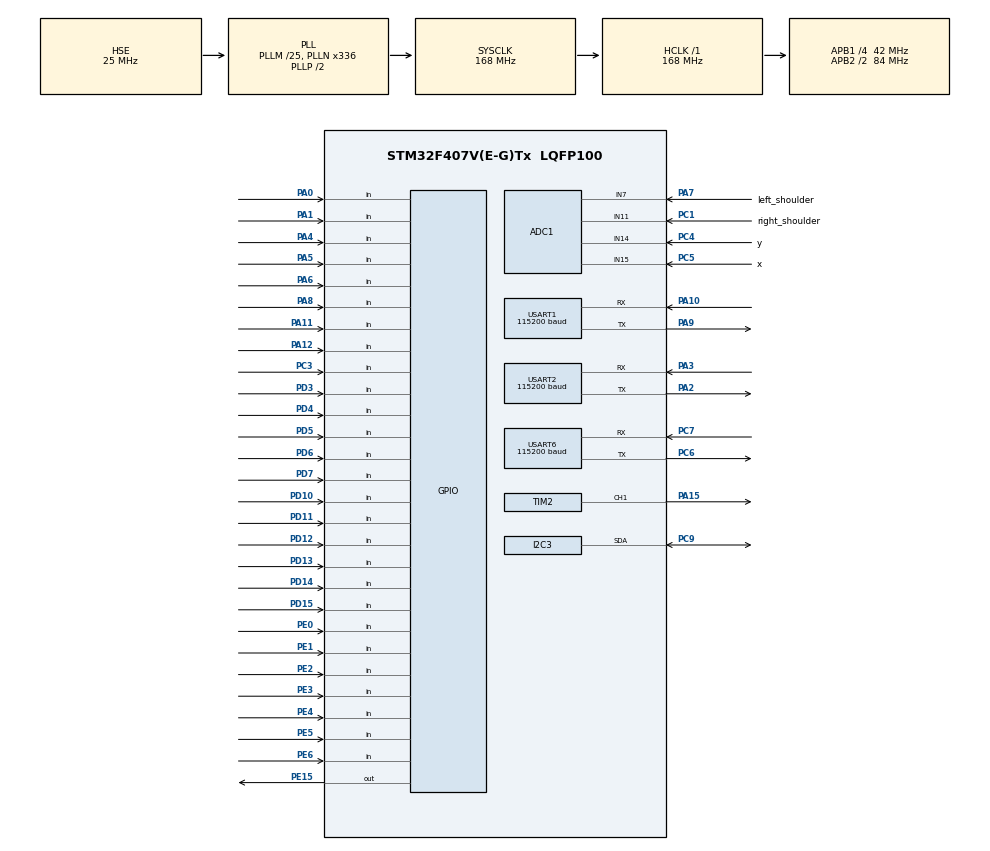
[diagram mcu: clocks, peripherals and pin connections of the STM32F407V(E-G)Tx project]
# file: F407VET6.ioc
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ADC1.Channel-0\#ChannelRegularConversion=ADC_CHANNEL_14
ADC1.Channel-1\#ChannelRegularConversion=ADC_CHANNEL_15
ADC1.Channel-2\#ChannelRegularConversion=ADC_CHANNEL_7
ADC1.Channel-3\#ChannelRegularConversion=ADC_CHANNEL_11
ADC1.NbrOfConversion=4
ADC1.NbrOfConversionFlag=1
ADC1.Rank-0\#ChannelRegularConversion=1
ADC1.Rank-1\#ChannelRegularConversion=2
ADC1.Rank-2\#ChannelRegularConversion=3
ADC1.Rank-3\#ChannelRegularConversion=4
ADC1.SamplingTime-0\#ChannelRegularConversion=ADC_SAMPLETIME_144CYCLES
ADC1.SamplingTime-1\#ChannelRegularConversion=ADC_SAMPLETIME_144CYCLES
ADC1.SamplingTime-2\#ChannelRegularConversion=ADC_SAMPLETIME_144CYCLES
ADC1.SamplingTime-3\#ChannelRegularConversion=ADC_SAMPLETIME_144CYCLES
ADC1.ScanConvMode=ENABLE
ADC1.master=1
Dma.ADC1.0.Direction=DMA_PERIPH_TO_MEMORY
Dma.ADC1.0.FIFOMode=DMA_FIFOMODE_DISABLE
Dma.ADC1.0.Instance=DMA2_Stream0
Dma.ADC1.0.MemDataAlignment=DMA_MDATAALIGN_HALFWORD
Dma.ADC1.0.MemInc=DMA_MINC_ENABLE
Dma.ADC1.0.Mode=DMA_NORMAL
Dma.ADC1.0.PeriphDataAlignment=DMA_PDATAALIGN_HALFWORD
Dma.ADC1.0.PeriphInc=DMA_PINC_DISABLE
Dma.ADC1.0.Priority=DMA_PRIORITY_LOW
Dma.Request0=ADC1
Dma.Request1=USART6_RX
Dma.Request2=USART6_TX
Dma.USART6_RX.1.Direction=DMA_PERIPH_TO_MEMORY
Dma.USART6_RX.1.FIFOMode=DMA_FIFOMODE_DISABLE
Dma.USART6_RX.1.Instance=DMA2_Stream1
Dma.USART6_RX.1.MemDataAlignment=DMA_MDATAALIGN_BYTE
Dma.USART6_RX.1.MemInc=DMA_MINC_ENABLE
Dma.USART6_RX.1.Mode=DMA_NORMAL
Dma.USART6_RX.1.PeriphDataAlignment=DMA_PDATAALIGN_BYTE
Dma.USART6_RX.1.PeriphInc=DMA_PINC_DISABLE
Dma.USART6_RX.1.Priority=DMA_PRIORITY_LOW
Dma.USART6_TX.2.Direction=DMA_MEMORY_TO_PERIPH
Dma.USART6_TX.2.FIFOMode=DMA_FIFOMODE_DISABLE
Dma.USART6_TX.2.Instance=DMA2_Stream6
Dma.USART6_TX.2.MemDataAlignment=DMA_MDATAALIGN_BYTE
Dma.USART6_TX.2.MemInc=DMA_MINC_ENABLE
Dma.USART6_TX.2.Mode=DMA_NORMAL
Dma.USART6_TX.2.PeriphDataAlignment=DMA_PDATAALIGN_BYTE
Dma.USART6_TX.2.PeriphInc=DMA_PINC_DISABLE
Dma.USART6_TX.2.Priority=DMA_PRIORITY_LOW
FREERTOS.BinarySemaphores01=myWIFIsuc,Dynamic,NULL,Depleted;myPacksuc,Dynamic,NULL,Depleted
FREERTOS.Queues01=ScanToTrans,1,remote_data,0,Dynamic,NULL,NULL
FREERTOS.Tasks01=myScanTask,24,256,ScanTask,As weak,NULL,Dynamic,NULL,NULL;myTransmitTask,24,256,TransmitTask,As weak,NULL,Dynamic,NULL,NULL;myWifiTask,24,256,WifiTask,As weak,NULL,Dynamic,NULL,NULL
Mcu.Family=STM32F4
Mcu.Name=STM32F407V(E-G)Tx
Mcu.Package=LQFP100
NVIC.ADC_IRQn=true\:5\:0\:false\:false\:true\:true\:true\:true\:true
NVIC.DMA2_Stream0_IRQn=true\:5\:0\:false\:false\:true\:true\:false\:true\:true
NVIC.DMA2_Stream1_IRQn=true\:5\:0\:false\:false\:true\:true\:false\:true\:true
NVIC.DMA2_Stream6_IRQn=true\:5\:0\:false\:false\:true\:true\:false\:true\:true
NVIC.PriorityGroup=NVIC_PRIORITYGROUP_4
NVIC.TIM1_UP_TIM10_IRQn=true\:15\:0\:false\:false\:true\:false\:false\:true\:true
NVIC.TimeBase=TIM1_UP_TIM10_IRQn
NVIC.TimeBaseIP=TIM1
PA0-WKUP.GPIO_PuPd=GPIO_PULLUP
PA0-WKUP.Signal=GPIO_Input
PA1.GPIO_PuPd=GPIO_PULLUP
PA1.Signal=GPIO_Input
PA10.Mode=Asynchronous
PA10.Signal=USART1_RX
PA11.GPIO_PuPd=GPIO_PULLUP
PA11.Signal=GPIO_Input
PA12.GPIO_PuPd=GPIO_PULLUP
PA12.Signal=GPIO_Input
PA13.Mode=Serial_Wire
PA13.Signal=SYS_JTMS-SWDIO
PA14.Mode=Serial_Wire
PA14.Signal=SYS_JTCK-SWCLK
PA15.GPIO_Speed=GPIO_SPEED_FREQ_LOW
PA15.Signal=S_TIM2_CH1_ETR
PA2.Mode=Asynchronous
PA2.Signal=USART2_TX
PA3.Mode=Asynchronous
PA3.Signal=USART2_RX
PA4.GPIO_PuPd=GPIO_PULLUP
PA4.Signal=GPIO_Input
PA5.GPIO_PuPd=GPIO_PULLUP
PA5.Signal=GPIO_Input
PA6.GPIO_PuPd=GPIO_PULLUP
PA6.Signal=GPIO_Input
PA7.GPIO_Label=left_shoulder
PA7.Signal=ADCx_IN7
PA8.GPIO_PuPd=GPIO_PULLUP
PA8.Signal=GPIO_Input
PA9.Mode=Asynchronous
PA9.Signal=USART1_TX
PC1.GPIO_Label=right_shoulder
PC1.Signal=ADCx_IN11
PC3.GPIO_PuPd=GPIO_PULLUP
PC3.Signal=GPIO_Input
PC4.GPIO_Label=y
PC4.Signal=ADCx_IN14
PC5.GPIO_Label=x
PC5.Signal=ADCx_IN15
PC6.Mode=Asynchronous
PC6.Signal=USART6_TX
PC7.Mode=Asynchronous
PC7.Signal=USART6_RX
PC9.Mode=I2C
PC9.Signal=I2C3_SDA
PD10.GPIO_PuPd=GPIO_PULLUP
PD10.Signal=GPIO_Input
PD11.GPIO_PuPd=GPIO_PULLUP
PD11.Signal=GPIO_Input
PD12.GPIO_PuPd=GPIO_PULLUP
PD12.Signal=GPIO_Input
PD13.GPIO_PuPd=GPIO_PULLUP
PD13.Signal=GPIO_Input
PD14.GPIO_PuPd=GPIO_PULLUP
PD14.Signal=GPIO_Input
PD15.GPIO_PuPd=GPIO_PULLUP
PD15.Signal=GPIO_Input
PD3.GPIO_PuPd=GPIO_PULLUP
PD3.Signal=GPIO_Input
PD4.GPIO_PuPd=GPIO_PULLUP
PD4.Signal=GPIO_Input
PD5.GPIO_PuPd=GPIO_PULLUP
PD5.Signal=GPIO_Input
PD6.GPIO_PuPd=GPIO_PULLUP
PD6.Signal=GPIO_Input
PD7.GPIO_PuPd=GPIO_PULLUP
PD7.Signal=GPIO_Input
PE0.GPIO_PuPd=GPIO_PULLUP
PE0.Signal=GPIO_Input
PE1.GPIO_PuPd=GPIO_PULLUP
PE1.Signal=GPIO_Input
PE15.GPIO_PuPd=GPIO_PULLDOWN
PE15.GPIO_Speed=GPIO_SPEED_FREQ_HIGH
PE15.Signal=GPIO_Output
PE2.GPIO_PuPd=GPIO_PULLUP
PE2.Signal=GPIO_Input
PE3.GPIO_PuPd=GPIO_PULLUP
PE3.Signal=GPIO_Input
PE4.GPIO_PuPd=GPIO_PULLUP
PE4.Signal=GPIO_Input
PE5.GPIO_PuPd=GPIO_PULLUP
PE5.Signal=GPIO_Input
PE6.GPIO_PuPd=GPIO_PULLUP
PE6.Signal=GPIO_Input
PH0-OSC_IN.Mode=HSE-External-Oscillator
PH0-OSC_IN.Signal=RCC_OSC_IN
PH1-OSC_OUT.Mode=HSE-External-Oscillator
PH1-OSC_OUT.Signal=RCC_OSC_OUT
ProjectManager.HeapSize=0x200
ProjectManager.StackSize=0x400
ProjectManager.TargetToolchain=MDK-ARM V5.32
RCC.48MHZClocksFreq_Value=84000000
RCC.AHBFreq_Value=168000000
RCC.APB1CLKDivider=RCC_HCLK_DIV4
RCC.APB1Freq_Value=42000000
RCC.APB1TimFreq_Value=84000000
RCC.APB2CLKDivider=RCC_HCLK_DIV2
RCC.APB2Freq_Value=84000000
RCC.APB2TimFreq_Value=168000000
RCC.CortexFreq_Value=168000000
RCC.HCLKFreq_Value=168000000
RCC.HSE_VALUE=25000000
RCC.HSI_VALUE=16000000
RCC.LSE_VALUE=32768
RCC.PLLM=25
RCC.PLLN=336
RCC.PLLSourceVirtual=RCC_PLLSOURCE_HSE
RCC.SYSCLKFreq_VALUE=168000000
RCC.SYSCLKSource=RCC_SYSCLKSOURCE_PLLCLK
RCC.VCOOutputFreq_Value=336000000
SH.ADCx_IN11.0=ADC1_IN11,IN11
SH.ADCx_IN14.0=ADC1_IN14,IN14
SH.ADCx_IN15.0=ADC1_IN15,IN15
SH.ADCx_IN7.0=ADC1_IN7,IN7
SH.S_TIM2_CH1_ETR.0=TIM2_CH1,PWM Generation1 CH1
TIM2.AutoReloadPreload=TIM_AUTORELOAD_PRELOAD_DISABLE
TIM2.Channel-PWM\ Generation1\ CH1=TIM_CHANNEL_1
TIM2.OC1Preload_PWM=DISABLE
TIM2.Period=28965
TIM2.Prescaler=0
TIM2.Pulse-PWM\ Generation1\ CH1=14482
USART1.BaudRate=115200
USART1.VirtualMode=VM_ASYNC
USART2.BaudRate=115200
USART2.VirtualMode=VM_ASYNC
USART6.BaudRate=115200
USART6.VirtualMode=VM_ASYNC
VP_FREERTOS_VS_CMSIS_V2.Mode=CMSIS_V2
VP_SYS_VS_tim1.Mode=TIM1
VP_TIM2_VS_ClockSourceINT.Mode=Internal
board=custom

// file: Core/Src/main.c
/* USER CODE BEGIN Header */
/**
  ******************************************************************************
  * @file           : main.c
  * @brief          : Main program body
  ******************************************************************************
  * @attention
  *
  * Copyright (c) 2026 STMicroelectronics.
  * All rights reserved.
  *
  * This software is licensed under terms that can be found in the LICENSE file
  * in the root directory of this software component.
  * If no LICENSE file comes with this software, it is provided AS-IS.
  *
  ******************************************************************************
  */
/* USER CODE END Header */
#include "main.h"
#include "cmsis_os.h"
#include "adc.h"
#include "dma.h"
#include "tim.h"
#include "usart.h"
#include "gpio.h"

/* USER CODE BEGIN Includes */
#include "mymain.h"
/* USER CODE END Includes */

/* USER CODE BEGIN PV */
/* USER CODE BEGIN PV */

/* USER CODE END PV */

void SystemClock_Config(void);
void MX_FREERTOS_Init(void);

int main(void)
{

  /* MCU Configuration--------------------------------------------------------*/

  /* Reset of all peripherals, Initializes the Flash interface and the Systick. */
  HAL_Init();

  /* Configure the system clock */
  SystemClock_Config();

  /* Initialize all configured peripherals */
  MX_GPIO_Init();
  MX_DMA_Init();
  MX_USART1_UART_Init();
  MX_USART2_UART_Init();
  MX_USART6_UART_Init();
  MX_ADC1_Init();
  MX_TIM2_Init();

  /* Init scheduler */
  osKernelInitialize();  /* Call init function for freertos objects (in cmsis_os2.c) */
  MX_FREERTOS_Init();

  /* Start scheduler */
  osKernelStart();

  /* We should never get here as control is now taken by the scheduler */

  /* Infinite loop */
  while (1)
  {

  }
}

void SystemClock_Config(void)
{
  RCC_OscInitTypeDef RCC_OscInitStruct = {0};
  RCC_ClkInitTypeDef RCC_ClkInitStruct = {0};

  /** Configure the main internal regulator output voltage
  */
  __HAL_RCC_PWR_CLK_ENABLE();
  __HAL_PWR_VOLTAGESCALING_CONFIG(PWR_REGULATOR_VOLTAGE_SCALE1);

  /** Initializes the RCC Oscillators according to the specified parameters
  * in the RCC_OscInitTypeDef structure.
  */
  RCC_OscInitStruct.OscillatorType = RCC_OSCILLATORTYPE_HSE;
  RCC_OscInitStruct.HSEState = RCC_HSE_ON;
  RCC_OscInitStruct.PLL.PLLState = RCC_PLL_ON;
  RCC_OscInitStruct.PLL.PLLSource = RCC_PLLSOURCE_HSE;
  RCC_OscInitStruct.PLL.PLLM = 25;
  RCC_OscInitStruct.PLL.PLLN = 336;
  RCC_OscInitStruct.PLL.PLLP = RCC_PLLP_DIV2;
  RCC_OscInitStruct.PLL.PLLQ = 4;
  if (HAL_RCC_OscConfig(&RCC_OscInitStruct) != HAL_OK)
  {
    Error_Handler();
  }

  /** Initializes the CPU, AHB and APB buses clocks
  */
  RCC_ClkInitStruct.ClockType = RCC_CLOCKTYPE_HCLK|RCC_CLOCKTYPE_SYSCLK
                              |RCC_CLOCKTYPE_PCLK1|RCC_CLOCKTYPE_PCLK2;
  RCC_ClkInitStruct.SYSCLKSource = RCC_SYSCLKSOURCE_PLLCLK;
  RCC_ClkInitStruct.AHBCLKDivider = RCC_SYSCLK_DIV1;
  RCC_ClkInitStruct.APB1CLKDivider = RCC_HCLK_DIV4;
  RCC_ClkInitStruct.APB2CLKDivider = RCC_HCLK_DIV2;

  if (HAL_RCC_ClockConfig(&RCC_ClkInitStruct, FLASH_LATENCY_5) != HAL_OK)
  {
    Error_Handler();
  }
}

void HAL_TIM_PeriodElapsedCallback(TIM_HandleTypeDef *htim)
{
  if (htim->Instance == TIM1)
  {
    HAL_IncTick();
  }
}

void Error_Handler(void)
{
  __disable_irq();
  while (1)
  {
  }
}

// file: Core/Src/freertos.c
/* USER CODE BEGIN Header */
/**
  ******************************************************************************
  * File Name          : freertos.c
  * Description        : Code for freertos applications
  ******************************************************************************
  * @attention
  *
  * Copyright (c) 2026 STMicroelectronics.
  * All rights reserved.
  *
  * This software is licensed under terms that can be found in the LICENSE file
  * in the root directory of this software component.
  * If no LICENSE file comes with this software, it is provided AS-IS.
  *
  ******************************************************************************
  */
/* USER CODE END Header */

#include "FreeRTOS.h"
#include "task.h"
#include "main.h"
#include "cmsis_os.h"

/* USER CODE BEGIN Includes */
#include "mymain.h"

/* USER CODE END Includes */

/* Definitions for myScanTask */
osThreadId_t myScanTaskHandle;
const osThreadAttr_t myScanTask_attributes = {
  .name = "myScanTask",
  .stack_size = 256 * 4,
  .priority = (osPriority_t) osPriorityNormal,
};
/* Definitions for myTransmitTask */
osThreadId_t myTransmitTaskHandle;
const osThreadAttr_t myTransmitTask_attributes = {
  .name = "myTransmitTask",
  .stack_size = 256 * 4,
  .priority = (osPriority_t) osPriorityNormal,
};
/* Definitions for myWifiTask */
osThreadId_t myWifiTaskHandle;
const osThreadAttr_t myWifiTask_attributes = {
  .name = "myWifiTask",
  .stack_size = 256 * 4,
  .priority = (osPriority_t) osPriorityNormal,
};
/* Definitions for ScanToTrans */
osMessageQueueId_t ScanToTransHandle;
const osMessageQueueAttr_t ScanToTrans_attributes = {
  .name = "ScanToTrans"
};
/* Definitions for myWIFIsuc */
osSemaphoreId_t myWIFIsucHandle;
const osSemaphoreAttr_t myWIFIsuc_attributes = {
  .name = "myWIFIsuc"
};
/* Definitions for myPacksuc */
osSemaphoreId_t myPacksucHandle;
const osSemaphoreAttr_t myPacksuc_attributes = {
  .name = "myPacksuc"
};

void ScanTask(void *argument);
void TransmitTask(void *argument);
void WifiTask(void *argument);

void MX_FREERTOS_Init(void); /* (MISRA C 2004 rule 8.1) */

void MX_FREERTOS_Init(void) {

  /* Create the semaphores(s) */
  /* creation of myWIFIsuc */
  myWIFIsucHandle = osSemaphoreNew(1, 0, &myWIFIsuc_attributes);

  /* creation of myPacksuc */
  myPacksucHandle = osSemaphoreNew(1, 0, &myPacksuc_attributes);

  /* Create the queue(s) */
  /* creation of ScanToTrans */
  ScanToTransHandle = osMessageQueueNew (1, sizeof(remote_data), &ScanToTrans_attributes);

  /* Create the thread(s) */
  /* creation of myScanTask */
  myScanTaskHandle = osThreadNew(ScanTask, NULL, &myScanTask_attributes);

  /* creation of myTransmitTask */
  myTransmitTaskHandle = osThreadNew(TransmitTask, NULL, &myTransmitTask_attributes);

  /* creation of myWifiTask */
  myWifiTaskHandle = osThreadNew(WifiTask, NULL, &myWifiTask_attributes);

}

__weak void ScanTask(void *argument)
{
  for(;;)
  {
    osDelay(1);
  }
}

__weak void TransmitTask(void *argument)
{
  for(;;)
  {
    osDelay(1);
  }
}

__weak void WifiTask(void *argument)
{
  for(;;)
  {
    osDelay(1);
  }
}
